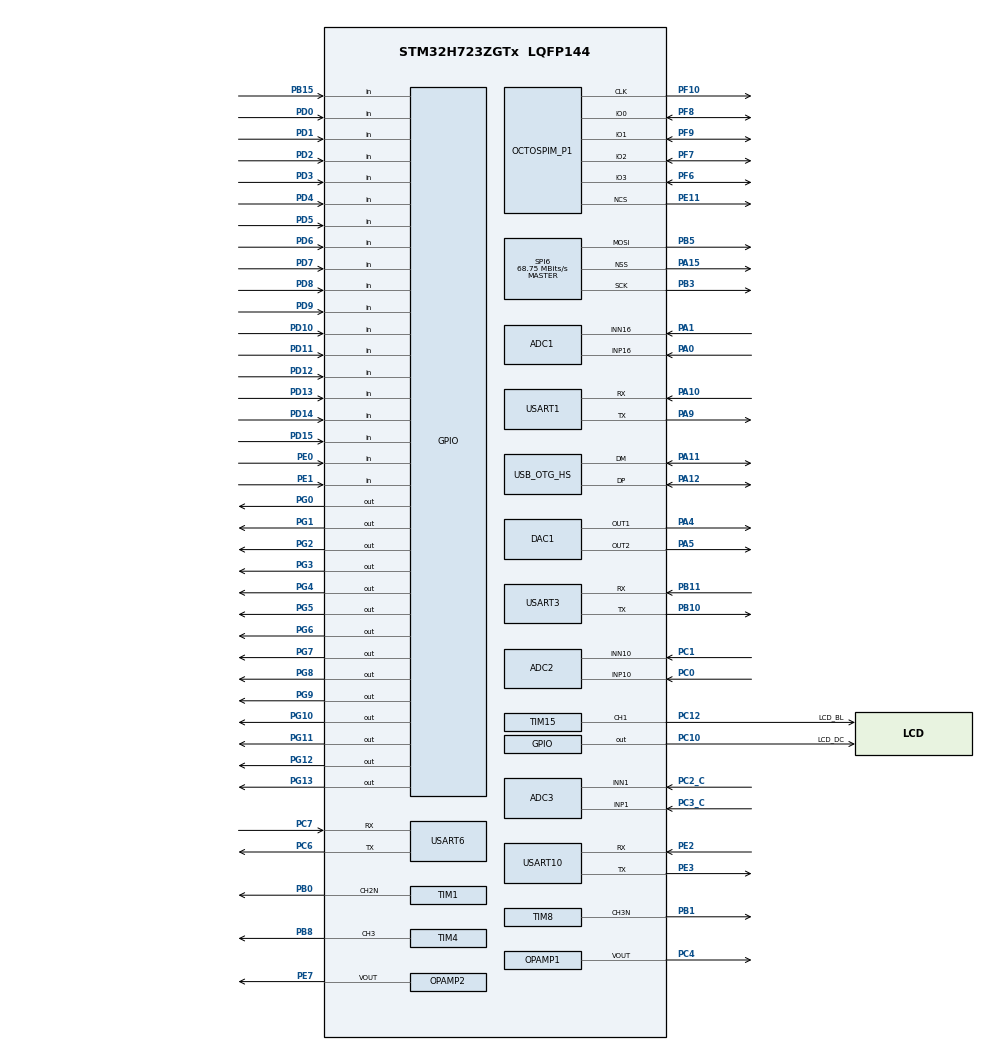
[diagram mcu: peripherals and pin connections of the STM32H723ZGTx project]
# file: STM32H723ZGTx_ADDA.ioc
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ADC1.Channel-0\#ChannelRegularConversion=ADC_CHANNEL_16
ADC1.NbrOfConversionFlag=1
ADC1.OffsetNumber-0\#ChannelRegularConversion=ADC_OFFSET_NONE
ADC1.OffsetSignedSaturation-0\#ChannelRegularConversion=DISABLE
ADC1.Rank-0\#ChannelRegularConversion=1
ADC1.SamplingTime-0\#ChannelRegularConversion=ADC_SAMPLETIME_1CYCLE_5
ADC1.SingleDiff-0\#ChannelRegularConversion=ADC_DIFFERENTIAL_ENDED
ADC1.master=1
ADC2.Channel-0\#ChannelRegularConversion=ADC_CHANNEL_10
ADC2.NbrOfConversionFlag=1
ADC2.OffsetNumber-0\#ChannelRegularConversion=ADC_OFFSET_NONE
ADC2.OffsetSignedSaturation-0\#ChannelRegularConversion=DISABLE
ADC2.Rank-0\#ChannelRegularConversion=1
ADC2.SamplingTime-0\#ChannelRegularConversion=ADC_SAMPLETIME_1CYCLE_5
ADC2.SingleDiff-0\#ChannelRegularConversion=ADC_DIFFERENTIAL_ENDED
ADC3.Channel-0\#ChannelRegularConversion=ADC_CHANNEL_1
ADC3.NbrOfConversionFlag=1
ADC3.OffsetNumber-0\#ChannelRegularConversion=ADC_OFFSET_NONE
ADC3.OffsetSign-0\#ChannelRegularConversion=ADC3_OFFSET_SIGN_NEGATIVE
ADC3.Rank-0\#ChannelRegularConversion=1
ADC3.SamplingTime-0\#ChannelRegularConversion=ADC3_SAMPLETIME_2CYCLES_5
ADC3.SingleDiff-0\#ChannelRegularConversion=ADC_DIFFERENTIAL_ENDED
DAC1.DAC_Channel-DAC_OUT1_ExtAndInt=DAC_CHANNEL_1
DAC1.DAC_Channel-DAC_OUT2_ExtAndInt=DAC_CHANNEL_2
Mcu.Family=STM32H7
Mcu.Name=STM32H723ZGTx
Mcu.Package=LQFP144
NVIC.PriorityGroup=NVIC_PRIORITYGROUP_4
PA0.Mode=IN16-Differential
PA0.Signal=ADC1_INP16
PA1.Mode=IN16-Differential
PA1.Signal=ADC1_INN16
PA10.Mode=Asynchronous
PA10.Signal=USART1_RX
PA11.Mode=Host_FS
PA11.Signal=USB_OTG_HS_DM
PA12.Mode=Host_FS
PA12.Signal=USB_OTG_HS_DP
PA13(JTMS/SWDIO).Mode=Serial_Wire
PA13(JTMS/SWDIO).Signal=DEBUG_JTMS-SWDIO
PA14(JTCK/SWCLK).Mode=Serial_Wire
PA14(JTCK/SWCLK).Signal=DEBUG_JTCK-SWCLK
PA15(JTDI).Mode=NSS_Signal_Hard_Output
PA15(JTDI).Signal=SPI6_NSS
PA4.Signal=COMP_DAC11_group
PA5.Signal=COMP_DAC12_group
PA9.Mode=Asynchronous
PA9.Signal=USART1_TX
PB0.GPIO_Speed=GPIO_SPEED_FREQ_VERY_HIGH
PB0.Mode=PWM Generation2 CH2N
PB0.Signal=TIM1_CH2N
PB1.GPIO_Speed=GPIO_SPEED_FREQ_VERY_HIGH
PB1.Mode=PWM Generation3 CH3N
PB1.Signal=TIM8_CH3N
PB10.Mode=Asynchronous
PB10.Signal=USART3_TX
PB11.Mode=Asynchronous
PB11.Signal=USART3_RX
PB15.Signal=GPIO_Input
PB3(JTDO/TRACESWO).Mode=TX_Only_Simplex_Unidirect_Master
PB3(JTDO/TRACESWO).Signal=SPI6_SCK
PB5.Mode=TX_Only_Simplex_Unidirect_Master
PB5.Signal=SPI6_MOSI
PB8.Signal=S_TIM4_CH3
PC0.Signal=ADCx_INP10
PC1.Signal=ADCx_INN10
PC10.GPIO_Label=LCD_DC
PC10.Signal=GPIO_Output
PC12.GPIO_Label=LCD_BL
PC12.Signal=S_TIM15_CH1
PC14-OSC32_IN.Mode=LSE-External-Oscillator
PC14-OSC32_IN.Signal=RCC_OSC32_IN
PC15-OSC32_OUT.Mode=LSE-External-Oscillator
PC15-OSC32_OUT.Signal=RCC_OSC32_OUT
PC2_C.Mode=IN1-Differential
PC2_C.Signal=ADC3_INN1
PC3_C.Mode=IN1-Differential
PC3_C.Signal=ADC3_INP1
PC4.Mode=Follower-DAC_OUT1-INP
PC4.Signal=OPAMP1_VOUT
PC6.Mode=Asynchronous
PC6.Signal=USART6_TX
PC7.Mode=Asynchronous
PC7.Signal=USART6_RX
PD0.Signal=GPIO_Input
PD1.Signal=GPIO_Input
PD10.Signal=GPIO_Input
PD11.Signal=GPIO_Input
PD12.Signal=GPIO_Input
PD13.Signal=GPIO_Input
PD14.Signal=GPIO_Input
PD15.Signal=GPIO_Input
PD2.Signal=GPIO_Input
PD3.Signal=GPIO_Input
PD4.Signal=GPIO_Input
PD5.Signal=GPIO_Input
PD6.Signal=GPIO_Input
PD7.Signal=GPIO_Input
PD8.Signal=GPIO_Input
PD9.Signal=GPIO_Input
PE0.Signal=GPIO_Input
PE1.Signal=GPIO_Input
PE11.Mode=OCTOSPI1_Port1_NCS
PE11.Signal=OCTOSPIM_P1_NCS
PE2.Mode=Asynchronous
PE2.Signal=USART10_RX
PE3.Mode=Asynchronous
PE3.Signal=USART10_TX
PE7.Mode=Follower-DAC_OUT2-INP
PE7.Signal=OPAMP2_VOUT
PF10.Mode=O1_P1_CLK
PF10.Signal=OCTOSPIM_P1_CLK
PF6.Mode=OCTOSPI1_IOL_Port1L
PF6.Signal=OCTOSPIM_P1_IO3
PF7.Mode=OCTOSPI1_IOL_Port1L
PF7.Signal=OCTOSPIM_P1_IO2
PF8.Mode=OCTOSPI1_IOL_Port1L
PF8.Signal=OCTOSPIM_P1_IO0
PF9.Mode=OCTOSPI1_IOL_Port1L
PF9.Signal=OCTOSPIM_P1_IO1
PG0.Signal=GPIO_Output
PG1.Signal=GPIO_Output
PG10.Signal=GPIO_Output
PG11.Signal=GPIO_Output
PG12.Signal=GPIO_Output
PG13.Signal=GPIO_Output
PG2.Signal=GPIO_Output
PG3.Signal=GPIO_Output
PG4.Signal=GPIO_Output
PG5.Signal=GPIO_Output
PG6.Signal=GPIO_Output
PG7.Signal=GPIO_Output
PG8.Signal=GPIO_Output
PG9.Signal=GPIO_Output
PH0-OSC_IN.Mode=HSE-External-Oscillator
PH0-OSC_IN.Signal=RCC_OSC_IN
PH1-OSC_OUT.Mode=HSE-External-Oscillator
PH1-OSC_OUT.Signal=RCC_OSC_OUT
ProjectManager.HeapSize=0x200
ProjectManager.StackSize=0x400
ProjectManager.TargetToolchain=MDK-ARM V5.32
RCC.ADCFreq_Value=96000671.38671875
RCC.APB1Freq_Value=137500000
RCC.APB2Freq_Value=137500000
RCC.APB3Freq_Value=137500000
RCC.APB4Freq_Value=137500000
RCC.CortexFreq_Value=550000000
RCC.D1PPRE=RCC_APB3_DIV2
RCC.D2PPRE1=RCC_APB1_DIV2
RCC.D2PPRE2=RCC_APB2_DIV2
RCC.D3PPRE=RCC_APB4_DIV2
RCC.DIVM1=2
RCC.DIVM2=2
RCC.DIVN1=44
RCC.DIVN2=15
RCC.DIVP1=1
RCC.DIVQ1=5
RCC.FLatency-AdvancedSettings=FLASH_LATENCY_3
RCC.HCLKFreq_Value=275000000
RCC.HPRE=RCC_HCLK_DIV2
RCC.PLL2FRACN=2950
RCC.PLL3FRACN=0
RCC.PLL3_VCO_SEL-AdvancedSettings=RCC_PLL3VCOMEDIUM
RCC.PLLFRACN=0
RCC.PLLSourceVirtual=RCC_PLLSOURCE_HSE
RCC.SYSCLKFreq_VALUE=550000000
RCC.SYSCLKSource=RCC_SYSCLKSOURCE_PLLCLK
RCC.USBFreq_Value=110000000
SH.ADCx_INN10.0=ADC2_INN10,IN10-Differential
SH.ADCx_INP10.0=ADC2_INP10,IN10-Differential
SH.COMP_DAC11_group.0=DAC1_OUT1,DAC_OUT1_ExtAndInt
SH.COMP_DAC12_group.0=DAC1_OUT2,DAC_OUT2_ExtAndInt
SH.S_TIM15_CH1.0=TIM15_CH1,PWM Generation1 CH1
SH.S_TIM4_CH3.0=TIM4_CH3,PWM Generation3 CH3
SPI6.CalculateBaudRate=68.75 MBits/s
SPI6.Direction=SPI_DIRECTION_2LINES_TXONLY
SPI6.Mode=SPI_MODE_MASTER
SPI6.VirtualNSS=VM_NSSHARD
SPI6.VirtualType=VM_MASTER
TIM1.Channel-PWM\ Generation2\ CH2N=TIM_CHANNEL_2
TIM15.Channel-PWM\ Generation1\ CH1=TIM_CHANNEL_1
TIM4.Channel-PWM\ Generation3\ CH3=TIM_CHANNEL_3
TIM8.Channel-PWM\ Generation3\ CH3N=TIM_CHANNEL_3
USART1.VirtualMode-Asynchronous=VM_ASYNC
USART10.VirtualMode-Asynchronous=VM_ASYNC
USART3.VirtualMode-Asynchronous=VM_ASYNC
USART6.VirtualMode-Asynchronous=VM_ASYNC
USB_OTG_HS.VirtualMode-Host_FS=Host_FS
VP_OCTOSPI1_VS_quad.Mode=quad_mode
VP_TIM15_VS_ClockSourceINT.Mode=Internal
VP_TIM1_VS_ClockSourceINT.Mode=Internal
VP_TIM4_VS_ClockSourceINT.Mode=Internal
VP_TIM8_VS_ClockSourceINT.Mode=Internal
board=custom

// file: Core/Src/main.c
/* USER CODE BEGIN Header */
/**
  ******************************************************************************
  * @file           : main.c
  * @brief          : Main program body
  ******************************************************************************
  * @attention
  *
  * Copyright (c) 2025 STMicroelectronics.
  * All rights reserved.
  *
  * This software is licensed under terms that can be found in the LICENSE file
  * in the root directory of this software component.
  * If no LICENSE file comes with this software, it is provided AS-IS.
  *
  ******************************************************************************
  */
/* USER CODE END Header */
#include "main.h"
#include "adc.h"
#include "dac.h"
#include "octospi.h"
#include "opamp.h"
#include "spi.h"
#include "tim.h"
#include "usart.h"
#include "usb_otg.h"
#include "gpio.h"

/* USER CODE BEGIN Includes */
#include "stdio.h"
/* USER CODE END Includes */

void SystemClock_Config(void);
void PeriphCommonClock_Config(void);

/* USER CODE BEGIN 0 */

int fputc(int ch, FILE *f)
{
  HAL_UART_Transmit(&huart1, (uint8_t *)&ch, 1, 0xffff);
  return ch;
}
/* USER CODE END 0 */

int main(void)
{

  /* MCU Configuration--------------------------------------------------------*/

  /* Reset of all peripherals, Initializes the Flash interface and the Systick. */
  HAL_Init();

  /* Configure the system clock */
  SystemClock_Config();

/* Configure the peripherals common clocks */
  PeriphCommonClock_Config();

  /* Initialize all configured peripherals */
  MX_GPIO_Init();
  MX_ADC1_Init();
  MX_ADC2_Init();
  MX_ADC3_Init();
  MX_DAC1_Init();
  MX_OCTOSPI1_Init();
  MX_OPAMP1_Init();
  MX_OPAMP2_Init();
  MX_SPI6_Init();
  MX_TIM15_Init();
  MX_USART1_UART_Init();
  MX_USB_OTG_HS_HCD_Init();
  MX_TIM1_Init();
  MX_TIM8_Init();
  MX_TIM4_Init();
  MX_USART3_UART_Init();
  MX_USART6_UART_Init();
  MX_USART10_UART_Init();
  /* USER CODE BEGIN 2 */
	printf("STM32H723ZGTx\r\n");
  /* USER CODE END 2 */

  /* Infinite loop */
  while (1)
  {

  }
}

void SystemClock_Config(void)
{
  RCC_OscInitTypeDef RCC_OscInitStruct = {0};
  RCC_ClkInitTypeDef RCC_ClkInitStruct = {0};

  /** Supply configuration update enable
  */
  HAL_PWREx_ConfigSupply(PWR_LDO_SUPPLY);

  /** Configure the main internal regulator output voltage
  */
  __HAL_PWR_VOLTAGESCALING_CONFIG(PWR_REGULATOR_VOLTAGE_SCALE0);

  while(!__HAL_PWR_GET_FLAG(PWR_FLAG_VOSRDY)) {}

  /** Initializes the RCC Oscillators according to the specified parameters
  * in the RCC_OscInitTypeDef structure.
  */
  RCC_OscInitStruct.OscillatorType = RCC_OSCILLATORTYPE_HSE;
  RCC_OscInitStruct.HSEState = RCC_HSE_ON;
  RCC_OscInitStruct.PLL.PLLState = RCC_PLL_ON;
  RCC_OscInitStruct.PLL.PLLSource = RCC_PLLSOURCE_HSE;
  RCC_OscInitStruct.PLL.PLLM = 2;
  RCC_OscInitStruct.PLL.PLLN = 44;
  RCC_OscInitStruct.PLL.PLLP = 1;
  RCC_OscInitStruct.PLL.PLLQ = 5;
  RCC_OscInitStruct.PLL.PLLR = 2;
  RCC_OscInitStruct.PLL.PLLRGE = RCC_PLL1VCIRANGE_3;
  RCC_OscInitStruct.PLL.PLLVCOSEL = RCC_PLL1VCOWIDE;
  RCC_OscInitStruct.PLL.PLLFRACN = 0;
  if (HAL_RCC_OscConfig(&RCC_OscInitStruct) != HAL_OK)
  {
    Error_Handler();
  }

  /** Initializes the CPU, AHB and APB buses clocks
  */
  RCC_ClkInitStruct.ClockType = RCC_CLOCKTYPE_HCLK|RCC_CLOCKTYPE_SYSCLK
                              |RCC_CLOCKTYPE_PCLK1|RCC_CLOCKTYPE_PCLK2
                              |RCC_CLOCKTYPE_D3PCLK1|RCC_CLOCKTYPE_D1PCLK1;
  RCC_ClkInitStruct.SYSCLKSource = RCC_SYSCLKSOURCE_PLLCLK;
  RCC_ClkInitStruct.SYSCLKDivider = RCC_SYSCLK_DIV1;
  RCC_ClkInitStruct.AHBCLKDivider = RCC_HCLK_DIV2;
  RCC_ClkInitStruct.APB3CLKDivider = RCC_APB3_DIV2;
  RCC_ClkInitStruct.APB1CLKDivider = RCC_APB1_DIV2;
  RCC_ClkInitStruct.APB2CLKDivider = RCC_APB2_DIV2;
  RCC_ClkInitStruct.APB4CLKDivider = RCC_APB4_DIV2;

  if (HAL_RCC_ClockConfig(&RCC_ClkInitStruct, FLASH_LATENCY_3) != HAL_OK)
  {
    Error_Handler();
  }
}

void PeriphCommonClock_Config(void)
{
  RCC_PeriphCLKInitTypeDef PeriphClkInitStruct = {0};

  /** Initializes the peripherals clock
  */
  PeriphClkInitStruct.PeriphClockSelection = RCC_PERIPHCLK_ADC;
  PeriphClkInitStruct.PLL2.PLL2M = 2;
  PeriphClkInitStruct.PLL2.PLL2N = 15;
  PeriphClkInitStruct.PLL2.PLL2P = 2;
  PeriphClkInitStruct.PLL2.PLL2Q = 2;
  PeriphClkInitStruct.PLL2.PLL2R = 2;
  PeriphClkInitStruct.PLL2.PLL2RGE = RCC_PLL2VCIRANGE_3;
  PeriphClkInitStruct.PLL2.PLL2VCOSEL = RCC_PLL2VCOWIDE;
  PeriphClkInitStruct.PLL2.PLL2FRACN = 2950;
  PeriphClkInitStruct.AdcClockSelection = RCC_ADCCLKSOURCE_PLL2;
  if (HAL_RCCEx_PeriphCLKConfig(&PeriphClkInitStruct) != HAL_OK)
  {
    Error_Handler();
  }
}

void Error_Handler(void)
{
  __disable_irq();
  while (1)
  {
  }
}
